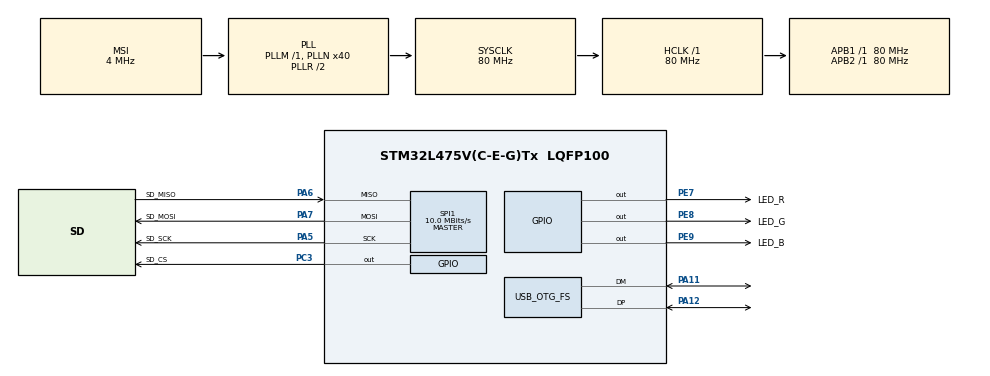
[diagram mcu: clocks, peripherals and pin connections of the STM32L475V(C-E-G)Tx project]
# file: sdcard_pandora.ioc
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FATFS._MAX_SS=4096
FATFS._USE_LFN=1
Mcu.Family=STM32L4
Mcu.Name=STM32L475V(C-E-G)Tx
Mcu.Package=LQFP100
NVIC.OTG_FS_IRQn=true\:0\:0\:false\:false\:true\:false\:true
NVIC.PriorityGroup=NVIC_PRIORITYGROUP_4
PA11.Mode=Device_Only
PA11.Signal=USB_OTG_FS_DM
PA12.Mode=Device_Only
PA12.Signal=USB_OTG_FS_DP
PA13\ (JTMS-SWDIO).Mode=Serial_Wire
PA13\ (JTMS-SWDIO).Signal=SYS_JTMS-SWDIO
PA14\ (JTCK-SWCLK).Mode=Serial_Wire
PA14\ (JTCK-SWCLK).Signal=SYS_JTCK-SWCLK
PA5.GPIO_Label=SD_SCK
PA5.Mode=Full_Duplex_Master
PA5.Signal=SPI1_SCK
PA6.GPIO_Label=SD_MISO
PA6.Mode=Full_Duplex_Master
PA6.Signal=SPI1_MISO
PA7.GPIO_Label=SD_MOSI
PA7.Mode=Full_Duplex_Master
PA7.Signal=SPI1_MOSI
PC3.GPIO_Label=SD_CS
PC3.PinState=GPIO_PIN_SET
PC3.Signal=GPIO_Output
PE7.GPIO_Label=LED_R
PE7.PinState=GPIO_PIN_SET
PE7.Signal=GPIO_Output
PE8.GPIO_Label=LED_G
PE8.PinState=GPIO_PIN_SET
PE8.Signal=GPIO_Output
PE9.GPIO_Label=LED_B
PE9.PinState=GPIO_PIN_SET
PE9.Signal=GPIO_Output
PH0-OSC_IN\ (PH0).Mode=HSE-External-Oscillator
PH0-OSC_IN\ (PH0).Signal=RCC_OSC_IN
PH1-OSC_OUT\ (PH1).Mode=HSE-External-Oscillator
PH1-OSC_OUT\ (PH1).Signal=RCC_OSC_OUT
ProjectManager.HeapSize=0x600
ProjectManager.StackSize=0x400
ProjectManager.TargetToolchain=MDK-ARM V5
RCC.ADCFreq_Value=48000000
RCC.AHBFreq_Value=80000000
RCC.APB1Freq_Value=80000000
RCC.APB1TimFreq_Value=80000000
RCC.APB2Freq_Value=80000000
RCC.APB2TimFreq_Value=80000000
RCC.CortexFreq_Value=80000000
RCC.HCLKFreq_Value=80000000
RCC.HSE_VALUE=8000000
RCC.HSI_VALUE=16000000
RCC.LSE_VALUE=32768
RCC.MSI_VALUE=4000000
RCC.PLLN=40
RCC.PLLSAI1N=24
RCC.SYSCLKFreq_VALUE=80000000
RCC.SYSCLKSource=RCC_SYSCLKSOURCE_PLLCLK
RCC.USBFreq_Value=48000000
RCC.VCOOutputFreq_Value=160000000
SPI1.BaudRatePrescaler=SPI_BAUDRATEPRESCALER_8
SPI1.CLKPhase=SPI_PHASE_2EDGE
SPI1.CLKPolarity=SPI_POLARITY_HIGH
SPI1.CalculateBaudRate=10.0 MBits/s
SPI1.DataSize=SPI_DATASIZE_8BIT
SPI1.Direction=SPI_DIRECTION_2LINES
SPI1.Mode=SPI_MODE_MASTER
SPI1.VirtualType=VM_MASTER
USB_DEVICE.CLASS_NAME_FS=CDC
USB_DEVICE.VirtualMode=Cdc
USB_DEVICE.VirtualModeFS=Cdc_FS
USB_OTG_FS.VirtualMode=Device_Only
VP_FATFS_VS_Generic.Mode=User_defined
VP_USB_DEVICE_VS_USB_DEVICE_CDC_FS.Mode=CDC_FS
board=custom

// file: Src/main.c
/* USER CODE BEGIN Header */
/**
  ******************************************************************************
  * @file           : main.c
  * @brief          : Main program body
  ******************************************************************************
  * @attention
  *
  * <h2><center>&copy; Copyright (c) 2019 STMicroelectronics.
  * All rights reserved.</center></h2>
  *
  * This software component is licensed by ST under Ultimate Liberty license
  * SLA0044, the "License"; You may not use this file except in compliance with
  * the License. You may obtain a copy of the License at:
  *                             www.st.com/SLA0044
  *
  ******************************************************************************
  */
/* USER CODE END Header */

#include "main.h"
#include "fatfs.h"
#include "usb_device.h"

/* USER CODE BEGIN Includes */
#include "Logger.h"
/* USER CODE END Includes */

SPI_HandleTypeDef hspi1;

void SystemClock_Config(void);
static void MX_GPIO_Init(void);
static void MX_SPI1_Init(void);

int main(void)
{

  /* MCU Configuration--------------------------------------------------------*/

  /* Reset of all peripherals, Initializes the Flash interface and the Systick. */
  HAL_Init();

  /* Configure the system clock */
  SystemClock_Config();

  /* Initialize all configured peripherals */
  MX_GPIO_Init();
  MX_FATFS_Init();
  MX_USB_DEVICE_Init();
  MX_SPI1_Init();
  /* USER CODE BEGIN 2 */
  Log_Init();

	int i;
	for(i=0;i<10;i++){
	  Write_Test(i,i);
	}

  /* USER CODE END 2 */

  /* Infinite loop */
  while (1)
  {

  }
}

void SystemClock_Config(void)
{
  RCC_OscInitTypeDef RCC_OscInitStruct = {0};
  RCC_ClkInitTypeDef RCC_ClkInitStruct = {0};
  RCC_PeriphCLKInitTypeDef PeriphClkInit = {0};

  /** Initializes the CPU, AHB and APB busses clocks
  */
  RCC_OscInitStruct.OscillatorType = RCC_OSCILLATORTYPE_MSI;
  RCC_OscInitStruct.MSIState = RCC_MSI_ON;
  RCC_OscInitStruct.MSICalibrationValue = 0;
  RCC_OscInitStruct.MSIClockRange = RCC_MSIRANGE_6;
  RCC_OscInitStruct.PLL.PLLState = RCC_PLL_ON;
  RCC_OscInitStruct.PLL.PLLSource = RCC_PLLSOURCE_MSI;
  RCC_OscInitStruct.PLL.PLLM = 1;
  RCC_OscInitStruct.PLL.PLLN = 40;
  RCC_OscInitStruct.PLL.PLLP = RCC_PLLP_DIV7;
  RCC_OscInitStruct.PLL.PLLQ = RCC_PLLQ_DIV2;
  RCC_OscInitStruct.PLL.PLLR = RCC_PLLR_DIV2;
  if (HAL_RCC_OscConfig(&RCC_OscInitStruct) != HAL_OK)
  {
    Error_Handler();
  }
  /** Initializes the CPU, AHB and APB busses clocks
  */
  RCC_ClkInitStruct.ClockType = RCC_CLOCKTYPE_HCLK|RCC_CLOCKTYPE_SYSCLK
                              |RCC_CLOCKTYPE_PCLK1|RCC_CLOCKTYPE_PCLK2;
  RCC_ClkInitStruct.SYSCLKSource = RCC_SYSCLKSOURCE_PLLCLK;
  RCC_ClkInitStruct.AHBCLKDivider = RCC_SYSCLK_DIV1;
  RCC_ClkInitStruct.APB1CLKDivider = RCC_HCLK_DIV1;
  RCC_ClkInitStruct.APB2CLKDivider = RCC_HCLK_DIV1;

  if (HAL_RCC_ClockConfig(&RCC_ClkInitStruct, FLASH_LATENCY_4) != HAL_OK)
  {
    Error_Handler();
  }
  PeriphClkInit.PeriphClockSelection = RCC_PERIPHCLK_USB;
  PeriphClkInit.UsbClockSelection = RCC_USBCLKSOURCE_PLLSAI1;
  PeriphClkInit.PLLSAI1.PLLSAI1Source = RCC_PLLSOURCE_MSI;
  PeriphClkInit.PLLSAI1.PLLSAI1M = 1;
  PeriphClkInit.PLLSAI1.PLLSAI1N = 24;
  PeriphClkInit.PLLSAI1.PLLSAI1P = RCC_PLLP_DIV7;
  PeriphClkInit.PLLSAI1.PLLSAI1Q = RCC_PLLQ_DIV2;
  PeriphClkInit.PLLSAI1.PLLSAI1R = RCC_PLLR_DIV2;
  PeriphClkInit.PLLSAI1.PLLSAI1ClockOut = RCC_PLLSAI1_48M2CLK;
  if (HAL_RCCEx_PeriphCLKConfig(&PeriphClkInit) != HAL_OK)
  {
    Error_Handler();
  }
  /** Configure the main internal regulator output voltage
  */
  if (HAL_PWREx_ControlVoltageScaling(PWR_REGULATOR_VOLTAGE_SCALE1) != HAL_OK)
  {
    Error_Handler();
  }
}

static void MX_SPI1_Init(void)
{

  /* SPI1 parameter configuration*/
  hspi1.Instance = SPI1;
  hspi1.Init.Mode = SPI_MODE_MASTER;
  hspi1.Init.Direction = SPI_DIRECTION_2LINES;
  hspi1.Init.DataSize = SPI_DATASIZE_8BIT;
  hspi1.Init.CLKPolarity = SPI_POLARITY_HIGH;
  hspi1.Init.CLKPhase = SPI_PHASE_2EDGE;
  hspi1.Init.NSS = SPI_NSS_SOFT;
  hspi1.Init.BaudRatePrescaler = SPI_BAUDRATEPRESCALER_8;
  hspi1.Init.FirstBit = SPI_FIRSTBIT_MSB;
  hspi1.Init.TIMode = SPI_TIMODE_DISABLE;
  hspi1.Init.CRCCalculation = SPI_CRCCALCULATION_DISABLE;
  hspi1.Init.CRCPolynomial = 7;
  hspi1.Init.CRCLength = SPI_CRC_LENGTH_DATASIZE;
  hspi1.Init.NSSPMode = SPI_NSS_PULSE_DISABLE;
  if (HAL_SPI_Init(&hspi1) != HAL_OK)
  {
    Error_Handler();
  }

}

static void MX_GPIO_Init(void)
{
  GPIO_InitTypeDef GPIO_InitStruct = {0};

  /* GPIO Ports Clock Enable */
  __HAL_RCC_GPIOH_CLK_ENABLE();
  __HAL_RCC_GPIOC_CLK_ENABLE();
  __HAL_RCC_GPIOA_CLK_ENABLE();
  __HAL_RCC_GPIOE_CLK_ENABLE();

  /*Configure GPIO pin Output Level */
  HAL_GPIO_WritePin(SD_CS_GPIO_Port, SD_CS_Pin, GPIO_PIN_SET);

  /*Configure GPIO pin Output Level */
  HAL_GPIO_WritePin(GPIOE, LED_R_Pin|LED_G_Pin|LED_B_Pin, GPIO_PIN_SET);

  /*Configure GPIO pin : SD_CS_Pin */
  GPIO_InitStruct.Pin = SD_CS_Pin;
  GPIO_InitStruct.Mode = GPIO_MODE_OUTPUT_PP;
  GPIO_InitStruct.Pull = GPIO_NOPULL;
  GPIO_InitStruct.Speed = GPIO_SPEED_FREQ_LOW;
  HAL_GPIO_Init(SD_CS_GPIO_Port, &GPIO_InitStruct);

  /*Configure GPIO pins : LED_R_Pin LED_G_Pin LED_B_Pin */
  GPIO_InitStruct.Pin = LED_R_Pin|LED_G_Pin|LED_B_Pin;
  GPIO_InitStruct.Mode = GPIO_MODE_OUTPUT_PP;
  GPIO_InitStruct.Pull = GPIO_NOPULL;
  GPIO_InitStruct.Speed = GPIO_SPEED_FREQ_LOW;
  HAL_GPIO_Init(GPIOE, &GPIO_InitStruct);

}

void Error_Handler(void)
{
}

/************************ (C) COPYRIGHT STMicroelectronics *****END OF FILE****/
